# nrf54lm20b_application register map
Vendor: Nordic Semiconductor; Series: nrf54l; File version: 1
CPU: CM33 r0p4, little endian, MPU, FPU, 3 interrupt priority bits, 270 interrupts, 4 SAU regions
Registers are 32-bit, read-write, reset 0x0 unless marked. A register's access mark holds for its fields unless they carry their own. Offsets are from the block's base; [hi:lo] are bit positions; lines under a group give offsets from that group; 'fields as' and 'values as' point back to an identical list.

## GLOBAL_USBHS_NS — USBHS 0
Base 0x4005A000
Same registers: GLOBAL_USBHS_S 0x5005A000
0x00 TASKS_START wo — Start the USB peripheral.
  [0] TASKS_START
    1=Trigger task
0x04 TASKS_STOP wo — Stop the USB peripheral
  [0] TASKS_STOP
    1=Trigger task
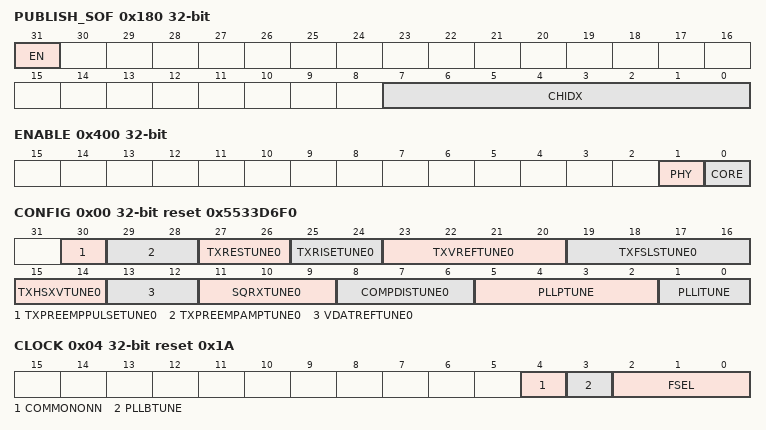
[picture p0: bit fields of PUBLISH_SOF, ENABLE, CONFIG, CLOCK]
0x180 PUBLISH_SOF — Publish configuration for SOF event.
  [31] EN — Enable publishing of SOF event
    0=Disabled (Disable publishing); 1=Enabled (Enable publishing)
  [7:0] CHIDX — DPPI channel to publish to
0x400 ENABLE — Enable USB peripheral.
  [1] PHY — Enable USB PHY
    0=Disabled (USB PHY disabled.); 1=Enabled (USB PHY enabled.)
  [0] CORE — Enable USB Controller
    0=Disabled (USB Controller disabled.); 1=Enabled (USB Controller enabled.)
0x440 PHY group — Unspecified
  0x00 CONFIG reset 0x5533D6F0 — USB PHY parameter overrides
    [30] TXPREEMPPULSETUNE0 — HS Transmitter Pre-Emphasis Duration Control
    [29:28] TXPREEMPAMPTUNE0 — HS Transmitter Pre-Emphasis Current Control
    [27:26] TXRESTUNE0 — USB Source Impedance Adjustment
    [25:24] TXRISETUNE0 — HS Transmitter Rise/Fall Time Adjustment
    [23:20] TXVREFTUNE0 — HS DC Voltage Level Adjustment
    [19:16] TXFSLSTUNE0 — FS/LS Source Impedance Adjustment
    [15:14] TXHSXVTUNE0 — Transmitter High-Speed Crossover Adjustment
    [13:12] VDATREFTUNE0 — Data Detect Voltage Adjustment
    [11:9] SQRXTUNE0 — Squelch Threshold Adjustment
    [8:6] COMPDISTUNE0 — Disconnect Threshold Adjustment
    [5:2] PLLPTUNE — PLL Proportional Path Tune
    [1:0] PLLITUNE — PLL Integral Path Tune
  0x04 CLOCK reset 0x1A — USB PHY clock configurations
    [4] COMMONONN — Common block power down control
      0=POWERED (The REFCLOCK_LOGIC,bias and PLL blocks are powered in sleep or suspend mode.); 1=SUSPEND (The REFCLOCK_LOGIC, bias and PLL blocks are powered down in suspend mode and bias and PLL blocks are powered down in sleep mode.)
    [3] PLLBTUNE — PLL bandwidth adjustment
      0=Disabled (PLL bandwidth adjustment disabled.); 1=Enabled (PLL bandwidth adjustment enabled.)
    [2:0] FSEL — Select reference clock frequency
      0=Clock19200KHz (Reference clock is 19.2MHz.); 1=Clock20000KHz (Reference clock is 20MHz.); 2=Clock24000KHz (Reference clock is 24MHz.); 7=Clock50000KHz (Reference clock is 50MHz.)
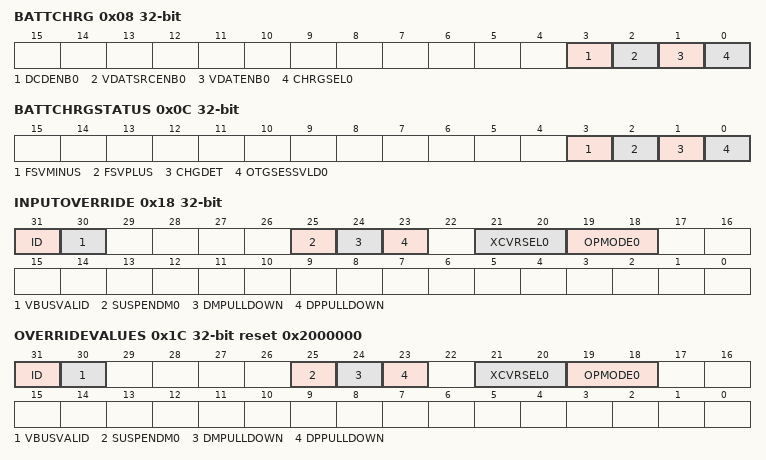
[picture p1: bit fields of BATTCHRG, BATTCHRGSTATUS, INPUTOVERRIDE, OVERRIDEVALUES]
  0x08 BATTCHRG — Battery Charging Configuration
    [3] DCDENB0 — Enhanced Data Contact Detection Enable
      0=Disabled (IDP_SRC current is disabled); 1=Enabled (IDP_SRC current is sourced onto DP0)
    [2] VDATSRCENB0 — Battery Charging Source Select
      0=Disabled (Data source voltage (VDAT_SRC) is disabled); 1=Enabled (Data source voltage (VDAT_SRC) is enabled)
    [1] VDATENB0 — Attach/Connect Detection Enable
      0=Disabled (Data detect voltage (CHG_DET) is disabled); 1=Enabled (Data detect voltage (CHG_DET) is enabled)
    [0] CHRGSEL0 — Battery charging source select
      0=SourceDP0SinkDM0 (Data source voltage (VDAT_SRC) is sourced onto DP0 and sunk from DM0); 1=SourceDM0SinkDP0 (Data source voltage (VDAT_SRC) is sourced onto DM0 and sunk from DP0)
  0x0C BATTCHRGSTATUS ro — Battery charger input signals
    [3] FSVMINUS, [2] FSVPLUS, [1] CHGDET, [0] OTGSESSVLD0
  0x18 INPUTOVERRIDE — Enables overriding of individual signals to the PHY, the override values are set in PHY.OVERRIDEVALUES
    [31] ID — Overrides OTG ID pin signal
    [30] VBUSVALID
    [25] SUSPENDM0
    [24] DMPULLDOWN
    [23] DPPULLDOWN
    [21:20] XCVRSEL0
      0=Disabled (Overrides are disabled); 3=Enabled (Overrides are enabled)
    [19:18] OPMODE0
      values as XCVRSEL0
  0x1C OVERRIDEVALUES reset 0x2000000 — Values that are used to override the input signals to the PHY.
    [31] ID — Overrides OTG ID pin signal
      1=Device (Role is Device); 0=Host (Role is Host.)
    [30] VBUSVALID — Signals to the PHY that VBUS is valid, and enables the pull-up resistor on D+
      1=Valid (VBUS is valid, and the pull-up resistor on D+ is enabled); 0=NotValid (VBUS is not valid, and the pull-up resistor on D+ is disabled.)
    [25] SUSPENDM0
    [24] DMPULLDOWN — This field controls the pull-down resistor on D-
      1=Enable (The pull-down resistor on D- is enabled); 0=Disable (The pull-down resistor on D- is disabled)
    [23] DPPULLDOWN — This field controls the pull-down resistor on D+
      1=Enable (The pull-down resistor on D+ is enabled); 0=Disable (The pull-down resistor on D+ is disabled)
    [21:20] XCVRSEL0
    [19:18] OPMODE0
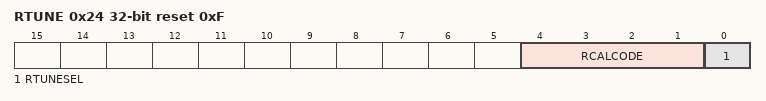
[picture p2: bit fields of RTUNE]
  0x24 RTUNE reset 0xF — The RTUNE mode is an alternative method for calibrating the DP and DM 45-Ohm source impedance.
    [4:1] RCALCODE — This signal is used to tune the internal 200 ohm resistor or the USBHS DP and DM high-speed source impedance.
    [0] RTUNESEL — This signal selects the tuning method for the high-speed DP and DM source impedance of the USBHS.
      1=TXRTUNE (The TXRTUNE pin, external resistor REXT, and resulting internal digital calibration code are used for tuning the high-speed source impedance.); 0=RTUNE (The RCALCODE value is used for tuning the high-speed source impedance.)
